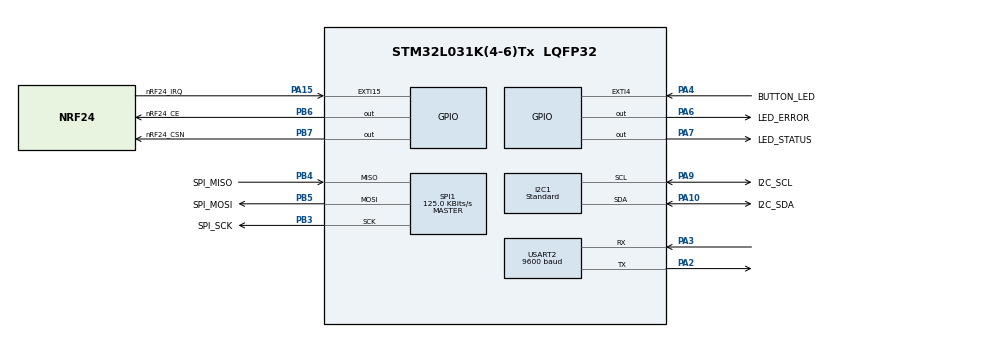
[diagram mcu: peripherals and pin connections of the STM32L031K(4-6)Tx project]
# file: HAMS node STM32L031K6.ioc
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ADC.ClockPrescaler=ADC_CLOCK_SYNC_PCLK_DIV4
ADC.OversamplingMode=ENABLE
ADC.Ratio=ADC_OVERSAMPLING_RATIO_32
ADC.RightBitShift=ADC_RIGHTBITSHIFT_5
ADC.SamplingTime=ADC_SAMPLETIME_12CYCLES_5
I2C1.I2C_Speed_Mode=I2C_Standard
I2C1.Timing=0x00201D2B
Mcu.Family=STM32L0
Mcu.Name=STM32L031K(4-6)Tx
Mcu.Package=LQFP32
NVIC.EXTI4_15_IRQn=true\:0\:0\:false\:false\:true\:true\:true\:true
NVIC.RTC_IRQn=true\:0\:0\:false\:false\:true\:true\:true\:true
NVIC.TIM21_IRQn=true\:0\:0\:false\:false\:true\:true\:true\:true
NVIC.TIM22_IRQn=true\:0\:0\:false\:false\:true\:true\:true\:true
PA10.GPIO_Label=I2C_SDA
PA10.GPIO_Speed=GPIO_SPEED_FREQ_LOW
PA10.Mode=I2C
PA10.Signal=I2C1_SDA
PA13.Mode=Serial_Wire
PA13.Signal=SYS_SWDIO
PA14.Mode=Serial_Wire
PA14.Signal=SYS_SWCLK
PA15.GPIO_Label=nRF24_IRQ
PA15.GPIO_ModeDefaultEXTI=GPIO_MODE_IT_FALLING
PA15.Signal=GPXTI15
PA2.Mode=Asynchronous
PA2.Signal=USART2_TX
PA3.Mode=Asynchronous
PA3.Signal=USART2_RX
PA4.GPIO_Label=BUTTON_LED
PA4.GPIO_ModeDefaultEXTI=GPIO_MODE_IT_FALLING
PA4.Signal=GPXTI4
PA6.GPIO_Label=LED_ERROR
PA6.Signal=GPIO_Output
PA7.GPIO_Label=LED_STATUS
PA7.Signal=GPIO_Output
PA9.GPIO_Label=I2C_SCL
PA9.GPIO_Speed=GPIO_SPEED_FREQ_LOW
PA9.Mode=I2C
PA9.Signal=I2C1_SCL
PB3.GPIO_Label=SPI_SCK
PB3.Mode=Full_Duplex_Master
PB3.Signal=SPI1_SCK
PB4.GPIO_Label=SPI_MISO
PB4.Mode=Full_Duplex_Master
PB4.Signal=SPI1_MISO
PB5.GPIO_Label=SPI_MOSI
PB5.Mode=Full_Duplex_Master
PB5.Signal=SPI1_MOSI
PB6.GPIO_Label=nRF24_CE
PB6.Signal=GPIO_Output
PB7.GPIO_Label=nRF24_CSN
PB7.Signal=GPIO_Output
PC14-OSC32_IN.GPIO_Label=LSE_IN
PC14-OSC32_IN.Mode=LSE-External-Oscillator
PC14-OSC32_IN.Signal=RCC_OSC32_IN
PC15-OSC32_OUT.GPIO_Label=LSE_OUT
PC15-OSC32_OUT.Mode=LSE-External-Oscillator
PC15-OSC32_OUT.Signal=RCC_OSC32_OUT
ProjectManager.HeapSize=0x200
ProjectManager.StackSize=0x400
ProjectManager.TargetToolchain=STM32CubeIDE
RCC.ADCFreq_Value=4000000
RCC.AHBFreq_Value=8000000
RCC.APB1Freq_Value=8000000
RCC.APB1TimFreq_Value=8000000
RCC.APB2Freq_Value=8000000
RCC.APB2TimFreq_Value=8000000
RCC.HCLKFreq_Value=8000000
RCC.HSE_VALUE=8000000
RCC.HSI16_VALUE=16000000
RCC.HSIRCDiv=4
RCC.HSI_VALUE=4000000
RCC.MSI_VALUE=2097000
RCC.PLLMUL=RCC_PLLMUL_4
RCC.RTCClockSelection=RCC_RTCCLKSOURCE_LSE
RCC.RTCClockSelectionVirtual=RCC_RTCCLKSOURCE_LSE
RCC.SYSCLKFreq_VALUE=8000000
RCC.SYSCLKSource=RCC_SYSCLKSOURCE_PLLCLK
RCC.VCOOutputFreq_Value=16000000
RTC.WakeUpClock-WakeUp=RTC_WAKEUPCLOCK_CK_SPRE_16BITS
RTC.WakeUpCounter-WakeUp=5
SPI1.BaudRatePrescaler=SPI_BAUDRATEPRESCALER_64
SPI1.CalculateBaudRate=125.0 KBits/s
SPI1.Direction=SPI_DIRECTION_2LINES
SPI1.Mode=SPI_MODE_MASTER
SPI1.VirtualType=VM_MASTER
TIM2.Prescaler=8
TIM21.Prescaler=80
TIM22.Prescaler=8
USART2.BaudRate=9600
USART2.Mode=MODE_TX
USART2.VirtualMode-Asynchronous=VM_ASYNC
VP_ADC_Vref_Input.Mode=IN-Vrefint
VP_CRC_VS_CRC.Mode=CRC_Activate
VP_RTC_VS_RTC_Activate.Mode=RTC_Enabled
VP_RTC_VS_RTC_WakeUp_intern.Mode=WakeUp
VP_TIM21_VS_ClockSourceINT.Mode=Internal
VP_TIM22_VS_ClockSourceINT.Mode=Internal
VP_TIM2_VS_ClockSourceINT.Mode=Internal
board=custom

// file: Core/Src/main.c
/* USER CODE BEGIN Header */
/**
  ******************************************************************************
  * @file           : main.c
  * @brief          : Main program body
  ******************************************************************************
  * @attention
  *
  * Copyright (c) 2024 STMicroelectronics.
  * All rights reserved.
  *
  * This software is licensed under terms that can be found in the LICENSE file
  * in the root directory of this software component.
  * If no LICENSE file comes with this software, it is provided AS-IS.
  *
  ******************************************************************************
  */
/* USER CODE END Header */
#include "main.h"
#include "adc.h"
#include "crc.h"
#include "i2c.h"
#include "rtc.h"
#include "spi.h"
#include "tim.h"
#include "usart.h"
#include "gpio.h"

/* USER CODE BEGIN Includes */
#include "app.h"
/* USER CODE END Includes */

void SystemClock_Config(void);

int main(void)
{

  /* MCU Configuration--------------------------------------------------------*/

  /* Reset of all peripherals, Initializes the Flash interface and the Systick. */
  LL_APB2_GRP1_EnableClock(LL_APB2_GRP1_PERIPH_SYSCFG);
  LL_APB1_GRP1_EnableClock(LL_APB1_GRP1_PERIPH_PWR);

  /* SysTick_IRQn interrupt configuration */
  NVIC_SetPriority(SysTick_IRQn, 3);

  /* Configure the system clock */
  SystemClock_Config();

  /* Initialize all configured peripherals */
  MX_GPIO_Init();
  MX_CRC_Init();
  MX_I2C1_Init();
  MX_TIM2_Init();
  MX_SPI1_Init();
  MX_TIM21_Init();
  MX_RTC_Init();
  MX_ADC_Init();
  MX_TIM22_Init();
  MX_USART2_UART_Init();
  /* USER CODE BEGIN 2 */
  app_setup();		// see app.h/c
  /* USER CODE END 2 */

  /* Infinite loop */
  /* USER CODE BEGIN WHILE */
  while (1)
  {
	  app_loop();	// see app.h/c
    /* USER CODE END WHILE */

  }
}

void SystemClock_Config(void)
{
  LL_FLASH_SetLatency(LL_FLASH_LATENCY_0);
  while(LL_FLASH_GetLatency()!= LL_FLASH_LATENCY_0)
  {
  }
  LL_PWR_SetRegulVoltageScaling(LL_PWR_REGU_VOLTAGE_SCALE1);
  while (LL_PWR_IsActiveFlag_VOS() != 0)
  {
  }
  LL_RCC_HSI_EnableDivider();
  LL_RCC_HSI_Enable();

   /* Wait till HSI is ready */
  while(LL_RCC_HSI_IsReady() != 1)
  {

  }
  LL_RCC_HSI_SetCalibTrimming(16);
  LL_PWR_EnableBkUpAccess();
  if(LL_RCC_GetRTCClockSource() != LL_RCC_RTC_CLKSOURCE_LSE)
  {
    LL_RCC_ForceBackupDomainReset();
    LL_RCC_ReleaseBackupDomainReset();
  }
  LL_RCC_LSE_SetDriveCapability(LL_RCC_LSEDRIVE_LOW);
  LL_RCC_LSE_Enable();

   /* Wait till LSE is ready */
  while(LL_RCC_LSE_IsReady() != 1)
  {

  }
  if(LL_RCC_GetRTCClockSource() != LL_RCC_RTC_CLKSOURCE_LSE)
  {
    LL_RCC_SetRTCClockSource(LL_RCC_RTC_CLKSOURCE_LSE);
  }
  LL_RCC_EnableRTC();
  LL_RCC_PLL_ConfigDomain_SYS(LL_RCC_PLLSOURCE_HSI, LL_RCC_PLL_MUL_4, LL_RCC_PLL_DIV_2);
  LL_RCC_PLL_Enable();

   /* Wait till PLL is ready */
  while(LL_RCC_PLL_IsReady() != 1)
  {

  }
  LL_RCC_SetAHBPrescaler(LL_RCC_SYSCLK_DIV_1);
  LL_RCC_SetAPB1Prescaler(LL_RCC_APB1_DIV_1);
  LL_RCC_SetAPB2Prescaler(LL_RCC_APB2_DIV_1);
  LL_RCC_SetSysClkSource(LL_RCC_SYS_CLKSOURCE_PLL);

   /* Wait till System clock is ready */
  while(LL_RCC_GetSysClkSource() != LL_RCC_SYS_CLKSOURCE_STATUS_PLL)
  {

  }

  LL_Init1msTick(8000000);

  LL_SetSystemCoreClock(8000000);
  LL_RCC_SetUSARTClockSource(LL_RCC_USART2_CLKSOURCE_PCLK1);
  LL_RCC_SetI2CClockSource(LL_RCC_I2C1_CLKSOURCE_PCLK1);
}

void Error_Handler(void)
{
  __disable_irq();
  while (1)
  {
  }
}
